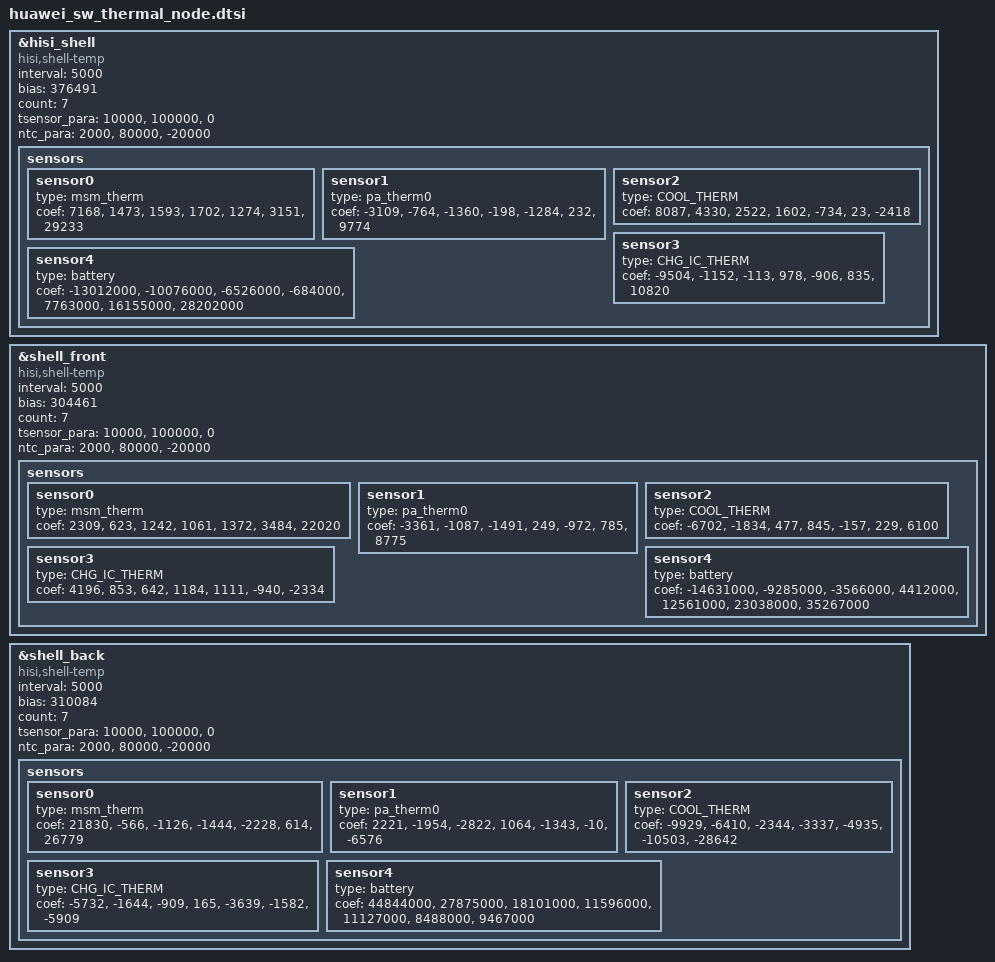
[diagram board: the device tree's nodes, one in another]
&hisi_shell {
	compatible = "hisi,shell-temp";
	interval = <5000>;
	bias = <376491>;
	count = <7>;
	tsensor_para = "10000","100000","0";
	ntc_para = "2000","80000","-20000";
	status = "ok";
	sensors {
		sensor0 {
			type = "msm_therm";
			coef = "7168","1473","1593","1702","1274","3151","29233";
		};
		sensor1 {
			type = "pa_therm0";
			coef = "-3109","-764","-1360","-198","-1284","232","9774";
		};
		sensor2 {
			type = "COOL_THERM";
			coef = "8087","4330","2522","1602","-734","23","-2418";
		};
		sensor3 {
			type = "CHG_IC_THERM";
			coef = "-9504","-1152","-113","978","-906","835","10820";
		};
		sensor4 {
			type = "battery";
			coef = "-13012000","-10076000","-6526000","-684000","7763000","16155000","28202000";
		};
	};
};

&shell_front {
	compatible = "hisi,shell-temp";
	interval = <5000>;
	bias = <304461>;
	count = <7>;
	tsensor_para = "10000","100000","0";
	ntc_para = "2000","80000","-20000";
	status = "ok";
	sensors {
		sensor0 {
			type = "msm_therm";
			coef = "2309","623","1242","1061","1372","3484","22020";
		};
		sensor1 {
			type = "pa_therm0";
			coef = "-3361","-1087","-1491","249","-972","785","8775";
		};
		sensor2 {
			type = "COOL_THERM";
			coef = "-6702","-1834","477","845","-157","229","6100";
		};
		sensor3 {
			type = "CHG_IC_THERM";
			coef = "4196","853","642","1184","1111","-940","-2334";
		};
		sensor4 {
			type = "battery";
			coef = "-14631000","-9285000","-3566000","4412000","12561000","23038000","35267000";
		};
	};
};

&shell_back {
	compatible = "hisi,shell-temp";
	interval = <5000>;
	bias = <310084>;
	count = <7>;
	tsensor_para = "10000","100000","0";
	ntc_para = "2000","80000","-20000";
	status = "ok";
	sensors {
		sensor0 {
			type = "msm_therm";
			coef = "21830","-566","-1126","-1444","-2228","614","26779";
		};
		sensor1 {
			type = "pa_therm0";
			coef = "2221","-1954","-2822","1064","-1343","-10","-6576";
		};
		sensor2 {
			type = "COOL_THERM";
			coef = "-9929","-6410","-2344","-3337","-4935","-10503","-28642";
		};
		sensor3 {
			type = "CHG_IC_THERM";
			coef = "-5732","-1644","-909","165","-3639","-1582","-5909";
		};
		sensor4 {
			type = "battery";
			coef = "44844000","27875000","18101000","11596000","11127000","8488000","9467000";
		};
	};
};

